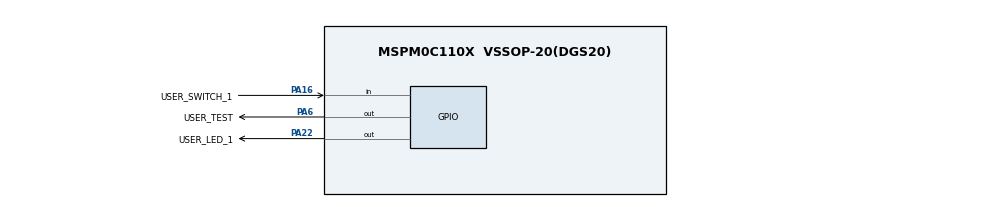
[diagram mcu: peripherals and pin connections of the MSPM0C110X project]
// @cliArgs --device "MSPM0C110X" --package "VSSOP-20(DGS20)" --part "Default"
// @cliArgs --board /ti/boards/LP_MSPM0C1104 --rtos nortos

/**
 * Import the modules used in this configuration.
 */
const GPIO   = scripting.addModule("/ti/driverlib/GPIO", {}, false);
const GPIO1  = GPIO.addInstance();
const GPIO2  = GPIO.addInstance();
const SYSCTL = scripting.addModule("/ti/driverlib/SYSCTL");

/**
 * Write custom configuration values to the imported modules.
 */
GPIO1.$name                          = "GPIO_LEDS";
GPIO1.associatedPins.create(2);
GPIO1.associatedPins[0].$name       = "USER_LED_1";
GPIO1.associatedPins[0].pin.$assign = "PA22";
GPIO1.associatedPins[0].subChanID       = 1;
GPIO1.associatedPins[0].subOutputPolicy = "TOGGLE";
GPIO1.associatedPins[0].initialValue    = "SET";
GPIO1.associatedPins[1].$name       = "USER_TEST";
GPIO1.associatedPins[1].pin.$assign = "PA6";
GPIO1.associatedPins[1].initialValue    = "SET";

const Board = scripting.addModule("/ti/driverlib/Board", {}, false);

GPIO2.$name                              = "GPIO_SWITCHES";
GPIO2.port                               = "PORTA";
GPIO2.associatedPins[0].$name            = "USER_SWITCH_1";
GPIO2.associatedPins[0].direction        = "INPUT";
GPIO2.associatedPins[0].pubChanID        = 1;
GPIO2.associatedPins[0].polarity         = "RISE_FALL";
GPIO2.associatedPins[0].internalResistor = "PULL_UP";
GPIO2.associatedPins[0].interruptEn      = true;
GPIO2.associatedPins[0].assignedPin      = "16";
GPIO2.associatedPins[0].pin.$assign      = "PA16";
